AUTOSAR XML (schema 4-2-2)
package /AUTOSAR/Components
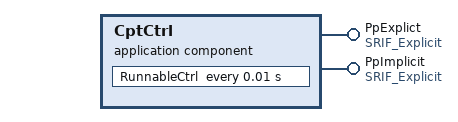
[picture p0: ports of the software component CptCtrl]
  application sw component type CptCtrl
    provide port PpExplict: provided-interface=SRIF_Explicit
    provide port PpImplicit: provided-interface=SRIF_Explicit
    behavior IbCtrl
      timing event timingEvent_10: start-on-event=RunnableCtrl, period=0.01
      runnable RunnableCtrl: symbol=AppRunnableCtrl
        data-send-points:
          access DataSendPointsPrimitive: accessed-variable=PpExplict.dataElementPrimitive
          access dataSendPointsArray: accessed-variable=PpExplict.dataElementArray
          access dataSendPointsStruct: accessed-variable=PpExplict.dataElementStruct
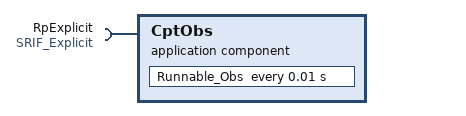
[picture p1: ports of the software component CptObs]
  application sw component type CptObs
    require port RpExplicit: required-interface=SRIF_Explicit
      required-com-specs:
        data-element=dataElementPrimitive, external-replacement=dataElementPrimitive, init-value=0
        data-element=dataElementStruct, init-value=fields=[0, 1, 2]
    behavior IbObs
      timing event timingEvent_10: start-on-event=Runnable_Obs, period=0.01
      runnable Runnable_Obs: symbol=AppRunnable_Obs
        data-receive-point-by-arguments:
          access DataReceiveByArgPrimitive: accessed-variable=RpExplicit.dataElementPrimitive
          access DataReceiveByArgArray: accessed-variable=RpExplicit.dataElementArray
          access DataReceiveByArgStruct: accessed-variable=RpExplicit.dataElementStruct
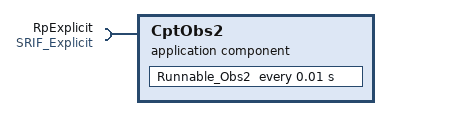
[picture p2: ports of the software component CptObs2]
  application sw component type CptObs2
    require port RpExplicit: required-interface=SRIF_Explicit
      required-com-specs:
        data-element=dataElementPrimitive, external-replacement=dataElementPrimitive, init-value=0
        data-element=dataElementStruct, init-value=fields=[0, 1, 2]
    behavior IbObs2
      timing event timingEvent_10: start-on-event=Runnable_Obs2, period=0.01
      runnable Runnable_Obs2: reentrancy-level=NON-REENTRANT, symbol=AppRunnable_Obs2
        data-receive-point-by-arguments:
          access DataReceiveByArgPrimitive: accessed-variable=RpExplicit.dataElementPrimitive
          access DataReceiveByArgArray: accessed-variable=RpExplicit.dataElementArray
          access DataReceiveByArgStruct: accessed-variable=RpExplicit.dataElementStruct
